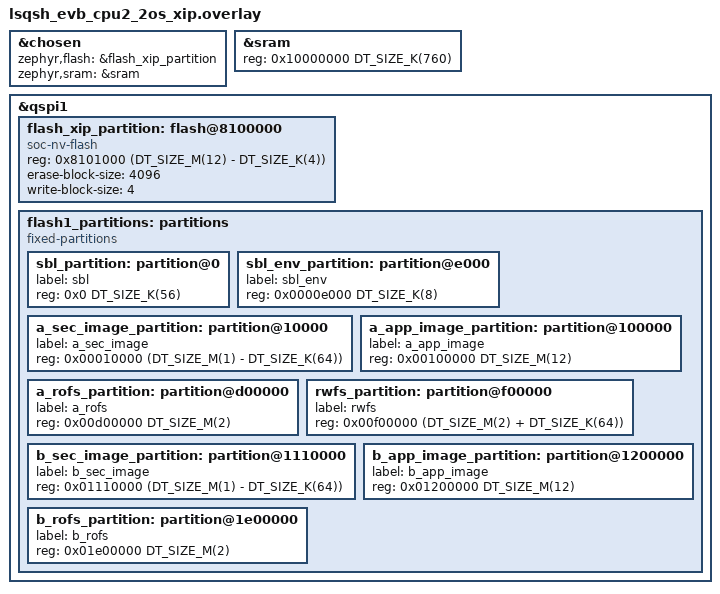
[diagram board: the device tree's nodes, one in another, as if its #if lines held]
/*
 * Copyright (c) 2025 linkedsemi
 * SPDX-License-Identifier: Apache-2.0
 */

#undef CONFIG_CPU2_IMAGE_HEADER

&chosen {
    zephyr,flash = &flash_xip_partition;
    zephyr,sram = &sram;
};

&sram {
    reg = <0x10000000 DT_SIZE_K(760)>;
};

&qspi1 {
    flash_xip_partition: flash@8100000 {
        compatible = "soc-nv-flash";
#if defined(CONFIG_CPU2_IMAGE_HEADER)
        reg = <0x8101000 (DT_SIZE_M(12) - DT_SIZE_K(4))>;
#else
        reg = <0x8100000 DT_SIZE_M(12)>;
#endif
        erase-block-size = <4096>;
        write-block-size = <4>;
    };

    flash1_partitions: partitions {
        compatible = "fixed-partitions";
        #address-cells = <1>;
        #size-cells = <1>;

        /* sbl */
        sbl_partition: partition@0 {
            label = "sbl";
            reg = <0x0 DT_SIZE_K(56)>;
        };
        sbl_env_partition: partition@e000 {
            label = "sbl_env";
            reg = <0x0000e000 DT_SIZE_K(8)>;
        };

        /* a */
        a_sec_image_partition: partition@10000 {
            label = "a_sec_image";
            reg = <0x00010000 (DT_SIZE_M(1) - DT_SIZE_K(64))>;
        };
        a_app_image_partition: partition@100000 {
            label = "a_app_image";
            reg = <0x00100000 DT_SIZE_M(12)>;
        };
        a_rofs_partition: partition@d00000 {
            label = "a_rofs";
            reg = <0x00d00000 DT_SIZE_M(2)>;
        };

        /* common */
        rwfs_partition: partition@f00000 {
            label = "rwfs";
            reg = <0x00f00000 (DT_SIZE_M(2) + DT_SIZE_K(64))>;
        };

        /* b */
        b_sec_image_partition: partition@1110000 {
            label = "b_sec_image";
            reg = <0x01110000 (DT_SIZE_M(1) - DT_SIZE_K(64))>;
        };
        b_app_image_partition: partition@1200000 {
            label = "b_app_image";
            reg = <0x01200000 DT_SIZE_M(12)>;
        };
        b_rofs_partition: partition@1e00000 {
            label = "b_rofs";
            reg = <0x01e00000 DT_SIZE_M(2)>;
        };
    };
};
